# 3066MNPIRH register map
File version: 1.0
Registers are 32-bit, access per field, reset 0x0 unless marked. A register's access mark holds for its fields unless they carry their own. Offsets are from the block's base; [hi:lo] are bit positions.

## CAN — CAN peripheral interface
Base 0x14600000
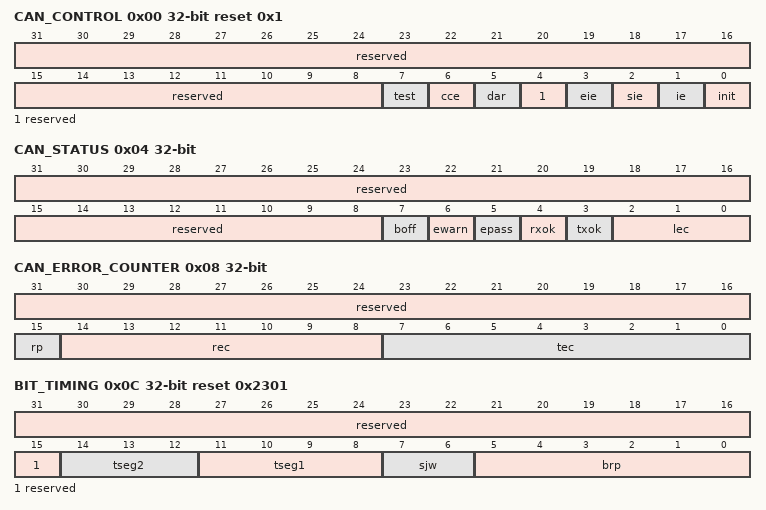
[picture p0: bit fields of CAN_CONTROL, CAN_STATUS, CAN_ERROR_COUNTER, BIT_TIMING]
0x00 CAN_CONTROL reset 0x1 — CAN_CONTROL为CAN 控制寄存器。
  [31:8] reserved ro — 保留。
  [7] test rw — 测试模式使能。 0：不使能； 1：使能。
  [6] cce rw — 更改配置使能。 0：禁止，CPU不能写Bit_Timing寄存器； 1：使能，当init为1时，CPU能写Bit_Timing寄存器。
  [5] dar rw — 关闭自动重传。 0：开启自动重传，自动重传受干扰的报文； 1：关闭自动重传。
  [4] reserved ro — 保留。
  [3] eie rw — 错误中断使能。 0：禁止； 1：使能错误中断，CAN_STATUS寄存器中的BOff或EWarn变化时会产生中断。
  [2] sie rw — 状态改变中断使能。 0：禁止； 1：使能状态改变中断，报文传输成功或检测到CAN总线错误时会产生中断。
  [1] ie rw — 模块中断使能。 0：禁止； 1：使能，CAN模块中断总开关。
  [0] init rw — 初始化使能。 0：禁止，此时CAN控制器正常工作； 1：使能，此时CAN控制器初始化。
0x04 CAN_STATUS — CAN_STATUS为CAN状态寄存器。
  [31:8] reserved ro — 保留。
  [7] boff ro — Bus-off状态。 0：CAN模块不处于Bus-off状态； 1：CAN模块处于Bus-off状态。
  [6] ewarn ro — 警告状态。 0：所有错误计数器均未达到96； 1：至少有一个错误计数器达到96。
  [5] epass ro — 错误状态。 0：处于CAN协议所定义的主动错误； 1：处于CAN协议所定义的被动错误。
  [4] rxok rw — 报文接收状态。 0：接收报文失败，rxok不会被CAN控制器复位； 1：接收报文成功（独立于报文接收过滤），rxok只有CPU可以清零。
  [3] txok rw — 报文发送状态。 0：发送报文失败，txok不会被CAN控制器复位； 1：发送报文成功（没有错误且被至少1个CAN节点应答），txok只有CPU可以清零。
  [2:0] lec rw — 错误状态码，用来表示CAN总线上最后一次错误状态。 000：无错误； 001：填充错误； 010：形式错误； 011：应答错误； 100：bit1错误； 101：bit0错误； 110：CRC错误； 111：未使用，没有检测到CAN总线事件，CPU最后将此值写入lec。
0x08 CAN_ERROR_COUNTER ro — CAN_ERROR_COUNTER为CAN错误计数寄存器。
  [31:16] reserved — 保留。
  [15] rp — 被动错误接收状态。 0：接收错误计数器未达到CAN协议所定义的被动错误水线； 1：接收错误计数器达到CAN协议所定义的被动错误水线。
  [14:8] rec — 接收错误计数器。 有效值在0～127。
  [7:0] tec — 发送错误计数器。 有效值在0～255。
0x0C BIT_TIMING reset 0x2301 — BIT_TIMING为位时间寄存器。
  [31:15] reserved ro — 保留。
  [14:12] tseg2 rw — 相位缓冲段2。 配置值为0～7，实际值比配置值多1。
  [11:8] tseg1 rw — 相位缓冲段1。 配置值为1～15，实际值比配置值多1。
  [7:6] sjw rw — 再同步跳转宽度。 配置值为0～3，实际值比配置值多1。
  [5:0] brp rw — 波特率系数。 配置值为0～63，实际值比配置值多1。
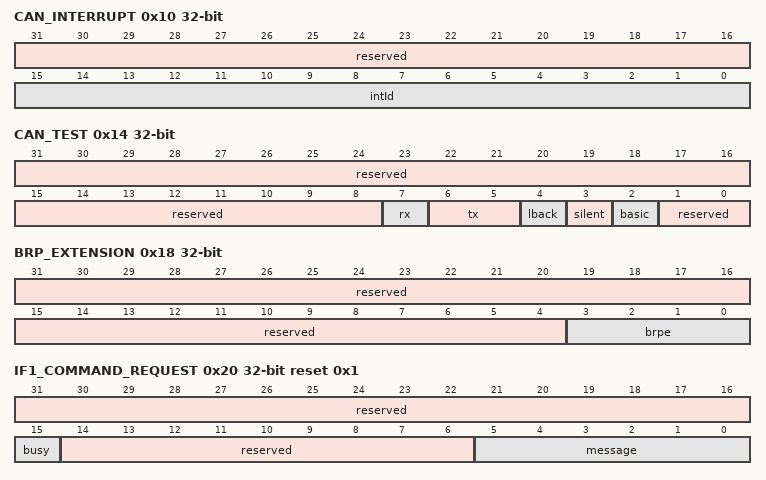
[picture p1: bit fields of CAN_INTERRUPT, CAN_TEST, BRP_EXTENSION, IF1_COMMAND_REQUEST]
0x10 CAN_INTERRUPT ro — CAN_INTERRUPT为CAN中断寄存器。
  [31:16] reserved — 保留。
  [15:0] intId — 中断ID。 0x0000：无中断； 0x0001：中断源是第1个报文对象； 0x0002：中断源是第2个报文对象； 0x0003：中断源是第3个报文对象； 0x0004：中断源是第4个报文对象； 0x0005：中断源是第5个报文对象； 0x0006：中断源是第6个报文对象； 0x0007：中断源是第7个报文对象； 0x0008：中断源是第8个报文对象； 0x0009：中断源是第9个报文对象； 0x000A：中断源是第10个报文对象； 0x000B：中断源是第11个报文对象； 0x000C：中断源是第12个报文对象； 0x000D：中断源是第13个报文对象； 0x000E：中断源是第14个报文对象； 0x000F：中断源是第15个报文对象； 0x0010：中断源是第16个报文对象； 0x0011：中断源是第17个报文对象； 0x0012：中断源是第18个报文对象； 0x0013：中断源是第19个报文对象； 0x0014：中断源是第20个报文对象； 0x0015：中断源是第21个报文对象； 0x0016：中断源是第22个报文对象； 0x0017：中断源是第23个报文对象； 0x0018：中断源是第24个报文对象； 0x0019：中断源是第25个报文对象； 0x001A：中断源是第26个报文对象； 0x001B：中断源是第27个报文对象； 0x001C：中断源是第28个报文对象； 0x001D：中断源是第29个报文对象； 0x001E：中断源是第30个报文对象； 0x001F：中断源是第31个报文对象； 0x0020：中断源是第32个报文对象； 0x0021 ～ 0x7FFF：无效； 0x8000：状态中断； 0x8001~0xFFFF：无效。
0x14 CAN_TEST — CAN_TEST为CAN调试寄存器。
  [31:8] reserved ro — 保留。
  [7] rx ro — CAN_RX管脚监控。 0：CAN总线为显性（CAN_RX=‘0’）； 1：CAN总线为隐形（CAN_RX=‘1’）。
  [6:5] tx rw — CAN_TX管脚控制。 00：不控制CAN_TX管脚； 01：采样点能被CAN_TX管脚监视； 10：CAN_TX管脚驱动显性值（‘0’）； 11：CAN_TX管脚驱动隐形值（‘1’）。
  [4] lback rw — Loop back模式使能。 0：禁止； 1：使能。
  [3] silent rw — Silent模式使能。 0：禁止； 1：使能。
  [2] basic rw — Basic模式使能。 0：禁止； 1：使能，此时IF1寄存器用作Tx Buffer，IF2寄存器用作Rx Buffer。
  [1:0] reserved ro — 保留。
0x18 BRP_EXTENSION — BRP_EXTENSION为BRP扩展寄存器。
  [31:4] reserved ro — 保留。
  [3:0] brpe rw — 波特率系数扩展。 扩展后的波特率系数有brpe和brp共同组成，其中高位是brpe，低位是brp。 此时，波特率系数的配置值最大可达到1023，实际值比配置值多1。
0x20 IF1_COMMAND_REQUEST reset 0x1 — IF1_COMMAND_REQUEST为IF1命令请求寄存器。
  [31:16] reserved ro — 保留。
  [15] busy ro — Busy标志。在Basic模式下，该位域可读可写。 0：IF1命令已经完成； 1：IF1命令执行中。
  [14:6] reserved ro — 保留。
  [5:0] message number rw — 报文对象序号。CPU写该位域后，IF1命令开始执行。 0x00：无效值，将指向0x20； 0x01 ～ 0x20：报文对象序号； 0x21 ~ 0x3F：无效值，将指向0x01 ~ 0x1F。
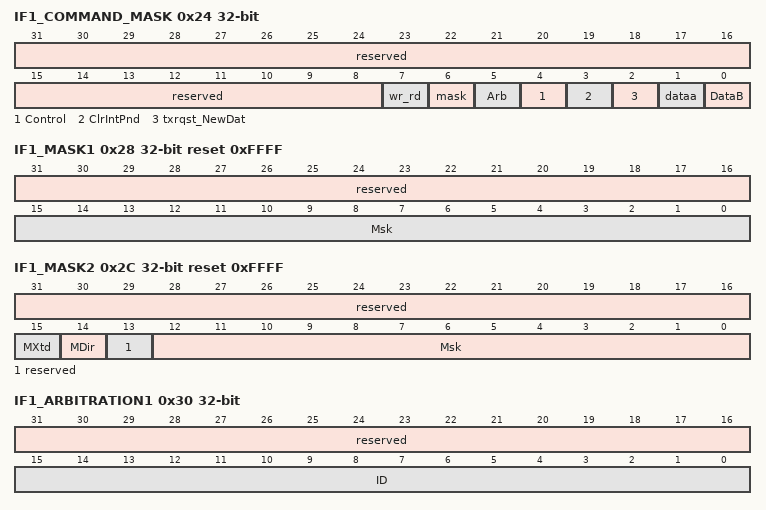
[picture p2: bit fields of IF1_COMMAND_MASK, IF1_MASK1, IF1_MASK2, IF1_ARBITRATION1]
0x24 IF1_COMMAND_MASK — IF1_COMMAND_MASK为IF1命令掩码寄存器。
  [31:8] reserved ro — 保留。
  [7] wr_rd rw — 读写命令，控制IF1报文缓冲寄存器和Message RAM传输方向。 0：读命令，将Message RAM中存储的报文对象回读到IF1报文缓冲寄存器； 1：写命令，将IF1报文缓冲寄存器写入到Message RAM中存储的报文对象。
  [6] mask rw — 命令掩码，控制IF1_MASK的传输。 当wr_rd为1，写命令时： 0：不写入，报文对象的msk、mdir、mxtd不改变； 1：将IF1_MASK1和IF1_MASK2寄存器中的msk、mdir、mxtd写入报文对象。 当wr_rd为0，读命令时： 0：不回读，IF1_MASK不改变； 1：将报文对象的Msk、Mdir、mxtd回读到IF1_MASK1和IF1_MASK2寄存器中。
  [5] Arb rw — 命令掩码，控制IF1_ARBITRATION的传输。 当wr_rd寄存器为1，写命令时： 0：不写入，报文对象的ID、Dir、Xtd、MsgVal不改变； 1：将IF1_ARBITRATION1和IF1_ARBITRATION2中的ID、Dir、Xtd、MsgVal位写入报文对象。 当wr_rd寄存器为0，读命令时： 0：不回读，IF1_ ARBITRATION不改变； 1：将报文对象的ID、Dir、Xtd、MsgVal回读到IF1_ARBITRATION1和IF1_ARBITRATION2寄存器中。
  [4] Control rw — 命令掩码，控制IF1_MESSAGE_CONTROL的传输。 当wr_rd寄存器为1，写命令时： 0：不写入，报文对象中的IF1_MESSAGE_CONTROL相关bit位不改变； 1：将IF1_MESSAGE_CONTROL的bit位写入报文对象。 当wr_rd寄存器为0，读命令时： 0：不回读，IF1_MESSAGE_CONTROL不改变； 1：将报文对象中的相应bit位回读到IF1_MESSAGE_CONTROL寄存器中。
  [3] ClrIntPnd rw — 命令掩码，清除报文对象的中断待处理。 当wr_rd寄存器为1，写命令时： 该位域忽略。 当wr_rd寄存器为0，读命令时： 0：报文对象的IntPnd位保持不变； 1：清除报文对象的IntPnd位。
  [2] txrqst_NewDat rw — 命令掩码，控制报文对象的txrqst位或者NewDat位。 当wr_rd寄存器为1时，写命令时： 访问txrqst位。 0：将IF1_MESSAGE_CONTROL寄存器的txrqst位写入报文对象； 1：忽略IF1_MESSAGE_CONTROL寄存器的txrqst位。直接置位报文对象的txrqst位，请求报文发送。 当wr_rd为0时，读命令时： 访问newdat位，IF1_MESSAGE_CONTROL寄存器的newdata位不会被更新。 0：报文对象的newdat位均保持不变； 1：清除报文对象的newdat位。
  [1] dataa rw — 命令掩码，控制IF1_DATAA的传输。 当wr_rd为1时，写命令时： 0：报文对象中的数据Byte 0～3保持不变； 1：将IF1_DATAA寄存器写入报文对象，更新报文对象中的数据Byte0~3。 当wr_rd寄存器为0时，读命令时： 0：IF1_DATAA寄存器保持不变； 1：将报文对象中的数据Byte0~3回读到IF1_DATAA寄存器中。
  [0] DataB rw — 命令掩码，控制IF1_DATAB的传输。 当wr_rd寄存器为1时，写命令时： 0：报文对象中的数据Byte 4～7保持不变； 1：将IF1_DATAB寄存器写入报文对象，更新报文对象中的数据Byte4~7。 当wr_rd寄存器为0时，读命令时： 0：IF1_DATAB寄存器保持不变； 1：将报文对象中的数据Byte4~7回读到IF1_DATAB寄存器中。
0x28 IF1_MASK1 reset 0xFFFF — IF1_MASK1为IF1掩码寄存器1。
  [31:16] reserved ro — 保留。
  [15:0] Msk rw — 报文对象ID第15位至第0位掩码，用于报文接收过滤。 0：ID第15位至第0位不用于报文接收过滤； 1：ID第15位至第0位用于报文接收过滤。
0x2C IF1_MASK2 reset 0xFFFF — IF1_MASK2为IF1掩码寄存器2。
  [31:16] reserved ro — 保留。
  [15] MXtd rw — 报文对象的拓展ID位（Xtd）掩码，用于接收报文过滤。 0：Xtd不用于报文接收过滤； 1：Xtd用于报文接收过滤。
  [14] MDir rw — 报文对象的方向位（Dir）掩码，用于接收报文过滤。 0：Dir不用于报文接收过滤； 1：Dir用于报文接收过滤。
  [13] reserved ro — 保留。
  [12:0] Msk rw — 报文对象ID第28位至第16位掩码，用于接收报文过滤。 0：ID第28位至第16位不用于报文接收过滤； 1：ID第28位至第16位用于报文接收过滤。
0x30 IF1_ARBITRATION1 — IF1_ARBITRATION1为IF1仲裁寄存器1。
  [31:16] reserved ro — 保留。
  [15:0] ID rw — 报文对象的报文ID第15位至第0位。 注意： 当报文对象用于收发扩展帧时，应使用全部ID；当报文对象用于收发标准帧时，应使用IF1_ARBITRATION2[ID]的高11位。
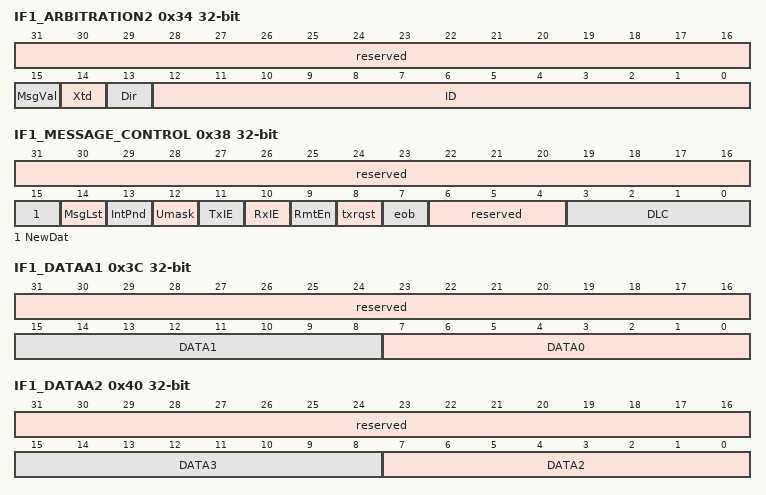
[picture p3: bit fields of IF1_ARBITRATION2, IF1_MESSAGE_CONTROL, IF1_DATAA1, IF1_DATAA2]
0x34 IF1_ARBITRATION2 — IF1_ARBITRATION2为IF1仲裁寄存器2。
  [31:16] reserved ro — 保留。
  [15] MsgVal rw — 报文对象有效使能。 0：禁止，该报文对象无效； 1：使能，该报文对象有效。
  [14] Xtd rw — 报文对象收发帧格式。 0：该报文对象收发标准格式帧； 1：该报文对象收发扩展格式帧。
  [13] Dir rw — 报文对象的方向。 0：报文对象为接收方向，接收报文； 1：报文对象为发送方向，发送报文。
  [12:0] ID rw — 报文对象的报文ID第28位至第16位。 注意： 当报文对象用于收发扩展帧时，应使用全部ID； 当报文对象用于收发标准帧时，应使用IF2_ARBITRATION2[ID]的高11位
0x38 IF1_MESSAGE_CONTROL — IF1_MESSAGE_CONTROL为IF1报文控制寄存器。
  [31:16] reserved ro — 保留。
  [15] NewDat rw — 报文对象的新数据写入状态。 报文对象为发送方向时： 0：无新的帧数据写入报文对象，报文对象成功发送后会清除报文对象中的NewDat； 1：有新的帧数据写入报文对象。 报文对象为接收方向时： 0：报文对象没有接收到新的帧； 1：报文对象接收到了新的帧。
  [14] MsgLst rw — 报文对象的报文丢失标识（仅在报文对象为接收方向时有效）。 0：报文对象无报文丢失； 1：报文对象有报文丢失，当报文对象的NewDat位未被清除，新的报文已接收时，报文对象的MsgLst置1。
  [13] IntPnd rw — 报文对象的中断待处理标识。 0：该报文对象不是中断源； 1：该报文对象是中断源。
  [12] Umask rw — 报文对象是否使用报文掩码，用于报文接收过滤。 0：不使用； 1：使用相关掩码位（Msk28～0，mxtd和Mdir用于报文接收过滤。
  [11] TxIE rw — 发送中断使能。 0：不使能，帧发送成功后IntPnd保持不变； 1：使能，帧发送成功后IntPnd将被至1。
  [10] RxIE rw — 接收中断使能。 0：不使能，帧接收成功后IntPnd保持不变； 1：使能，帧接收成功后IntPnd将被至1。
  [9] RmtEn rw — 远程帧使能。 0：不使能，接收远程帧后txrqst保持不变； 1：使能，接收远程帧后txrqst置1。
  [8] txrqst rw — 传输请求。 0：该报文对象没在等待传输； 1：该报文对象请求传输，并且还没传输完成。
  [7] eob rw — 多报文接收模式。 0：该报文对象不是多报文接收模式中最后一个报文对象； 1：该报文对象是单一报文或是多报文接收模式中最后一个报文对象。
  [6:4] reserved ro — 保留。
  [3:0] DLC rw — 数据长度编码。 0x0～0x8：数据帧有0~8个数据字节； 0x9~0xF：数据帧有8个数据字节。
0x3C IF1_DATAA1 — IF1_DATAA1为IF1数据A1寄存器。
  [31:16] reserved ro — 保留。
  [15:8] DATA1 rw — CAN帧数据Byte 1。
  [7:0] DATA0 rw — CAN帧数据Byte 0。
0x40 IF1_DATAA2 — IF1_DATAA2为IF1数据A2寄存器。
  [31:16] reserved ro — 保留。
  [15:8] DATA3 rw — CAN帧数据Byte 3。
  [7:0] DATA2 rw — CAN帧数据Byte 2。
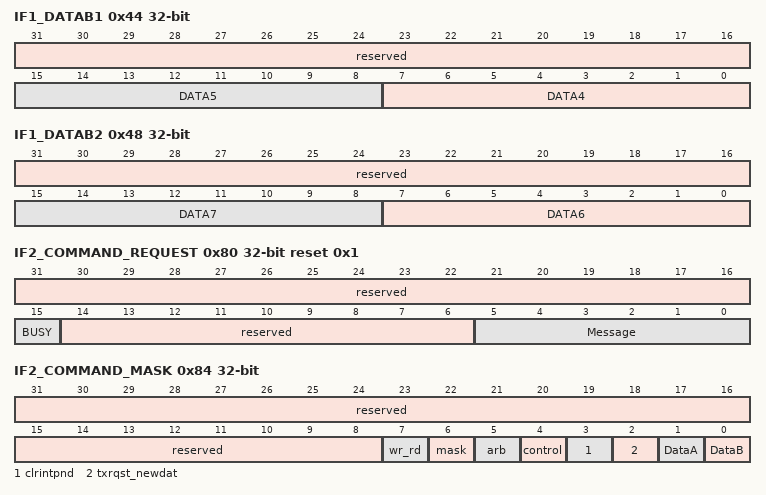
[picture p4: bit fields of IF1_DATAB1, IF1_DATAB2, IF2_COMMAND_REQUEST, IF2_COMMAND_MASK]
0x44 IF1_DATAB1 — IF1_DATAB1为IF1数据B1寄存器。
  [31:16] reserved ro — 保留。
  [15:8] DATA5 rw — CAN帧数据Byte 5。
  [7:0] DATA4 rw — CAN帧数据Byte 4。
0x48 IF1_DATAB2 — IF1_DATAB2为IF1数据B2寄存器。
  [31:16] reserved ro — 保留。
  [15:8] DATA7 rw — CAN帧数据Byte 7。
  [7:0] DATA6 rw — CAN帧数据Byte 6。
0x80 IF2_COMMAND_REQUEST reset 0x1 — IF2_COMMAND_REQUEST为IF2命令请求寄存器。
  [31:16] reserved ro — 保留。
  [15] BUSY ro — Busy标志。 0：IF2命令已经完成； 1：IF2命令执行中。
  [14:6] reserved ro — 保留。
  [5:0] Message Number rw — 报文对象序号。CPU写该位域后，IF2命令开始执行。 0x00：无效值，将指向0x20； 0x01～0x20：报文对象序号； 0x21~0x3F：无效值，将指向0x01~0x1F。
0x84 IF2_COMMAND_MASK — IF2_COMMAND_MASK为IF2命令掩码寄存器。
  [31:8] reserved ro — 保留。
  [7] wr_rd rw — 读写命令，控制IF2报文缓冲寄存器和Message RAM传输方向。 0：读命令，将Message RAM中存储的报文对象回读到IF2报文缓冲寄存器； 1：写命令，将IF2报文缓冲寄存器写入到Message RAM中存储的报文对象。
  [6] mask rw — 命令掩码，控制IF2_MASK的传输。 当wr_rd寄存器为1，写命令时： 0：不写入，报文对象的ID Mask、mdir、mxtd不改变； 1：将IF2_MASK1和IF2_MASK2寄存器中的ID Mask、mdir、mxtd写入报文对象。 当wr_rd寄存器为0，读命令时： 0：不回读，IF2_MASK不改变； 1：将报文对象的ID Mask、mdir、mxtd回读到IF2_MASK1和IF2_MASK2寄存器中。
  [5] arb rw — 命令掩码，控制IF2_ARBITRATION的传输。 当wr_rd寄存器为1，写命令时： 0：不写入，报文对象的ID、dir、xtd、msgval不改变； 1：将IF2_ARBITRATION1和IF2_ARBITRATION2中的ID、dir、xtd、msgval位写入报文对象。 当wr_rd寄存器为0，读命令时： 0：不回读，IF2_ARBITRATION不改变； 1：将报文对象的ID、dir、xtd、msgval回读到IF2_ARBITRATION1和IF2_ARBITRATION2寄存器中。
  [4] control rw — 命令掩码，控制IF2_MESSAGE_CONTROL的传输。 当wr_rd寄存器为1，写命令时： 0：不写入，报文对象中的IF2_MESSAGE_CONTROL相关bit位不改变； 1：将IF2_MESSAGE_CONTROL的bit位写入报文对象。 当wr_rd寄存器为0，读命令时： 0：不回读，IF2_MESSAGE_CONTROL不改变； 1：将报文对象中的相应bit位回读到IF2_MESSAGE_CONTROL寄存器中。
  [3] clrintpnd rw — 命令掩码，清除报文对象的中断待处理。 当wr_rd寄存器为1，写命令时： 该位域忽略。 当wr_rd寄存器为0，读命令时： 0：报文对象的intpnd位保持不变； 1：清除报文对象的intpnd位。
  [2] txrqst_newdat rw — 命令掩码，控制报文对象的txrqst位或者NewDat位。 当wr_rd寄存器为1时，写命令时： 访问txrqst位。 0：报文对象txrqst位保持不变； 1：置位报文对象的txrqst位，请求报文发送。 当wr_rd寄存器为0时，读命令时： 访问newdat位。 0：报文对象的newdat位保持不变； 1：清除报文对象的newdat位。
  [1] DataA rw — 命令掩码，控制IF2_DATAA的传输。 当wr_rd寄存器为1时，写命令时： 0：报文对象中的数据Byte 0～3保持不变； 1：将IF2_DATAA寄存器写入报文对象，更新报文对象中的数据Byte0~3。 当wr_rd寄存器为0时，读命令时： 0：IF2_DATAA寄存器保持不变； 1：将报文对象中的数据Byte0~3回读到IF2_DATAA寄存器中。
  [0] DataB rw — 命令掩码，控制IF2_DATAB的传输。 当wr_rd寄存器为1时，写命令时： 0：报文对象中的数据Byte 4～7保持不变； 1：将IF2_DATAB寄存器写入报文对象，更新报文对象中的数据Byte4~7。 当wr_rd寄存器为0时，读命令时： 0：IF2_DATAB寄存器保持不变； 1：将报文对象中的数据Byte4~7回读到IF2_DATAB寄存器中。
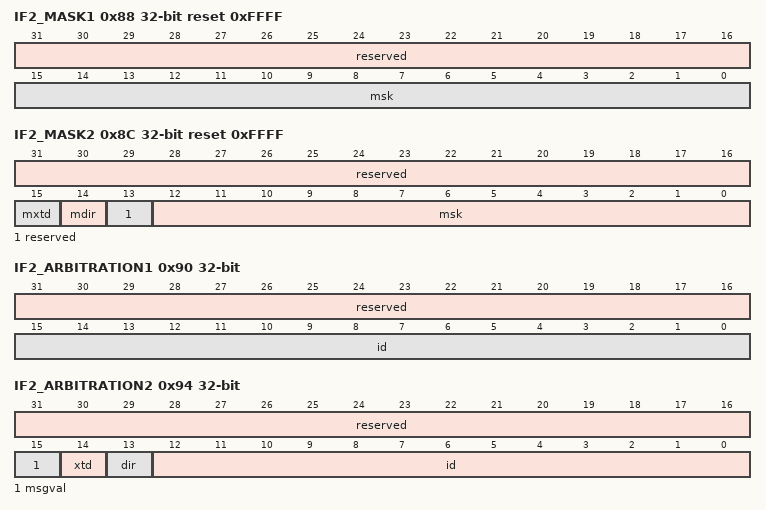
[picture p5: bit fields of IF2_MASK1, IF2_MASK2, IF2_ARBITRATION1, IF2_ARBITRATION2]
0x88 IF2_MASK1 reset 0xFFFF — IF2_MASK1为IF2掩码寄存器1。
  [31:16] reserved ro — 保留。
  [15:0] msk rw — 报文对象ID第15位至第0位掩码，用于报文接收过滤。 0：ID第15位至第0位不用于报文接收过滤； 1：ID第15位至第0位用于报文接收过滤。
0x8C IF2_MASK2 reset 0xFFFF — IF2_MASK2为IF2掩码寄存器2。
  [31:16] reserved ro — 保留。
  [15] mxtd rw — 报文对象的拓展ID位（xtd）掩码，用于报文接收过滤。 0：xtd不用于报文接收过滤； 1：xtd用于报文接收过滤。
  [14] mdir rw — 报文对象的方向位（dir）掩码，用于报文接收过滤。 0：dir不用于报文接收过滤； 1：dir用于报文接收过滤。
  [13] reserved ro — 保留。
  [12:0] msk rw — 报文对象ID第28位至第16位掩码，用于报文接收过滤。 0：ID第28位至第16位不用于报文接收过滤； 1：ID第28位至第16位用于报文接收过滤。
0x90 IF2_ARBITRATION1 — IF2_ARBITRATION1为IF2仲裁寄存器1。
  [31:16] reserved ro — 保留。
  [15:0] id rw — 报文对象的报文ID第15位至第0位。 注意： 当报文对象用于收发扩展帧时，应使用全部ID；当报文对象用于收发标准帧时，应使用IF2_ARBITRATION2[id]的高11位。
0x94 IF2_ARBITRATION2 — IF2_ARBITRATION2为IF2仲裁寄存器2。
  [31:16] reserved ro — 保留。
  [15] msgval rw — 报文对象有效使能。 0：禁止，该报文对象无效； 1：使能，该报文对象有效。
  [14] xtd rw — 报文对象收发帧格式。 0：该报文对象收发标准格式帧； 1：该报文对象收发扩展格式帧。
  [13] dir rw — 报文对象的方向。 0：报文对象为接收方向，接收报文； 1：报文对象为发送方向，发送报文。
  [12:0] id rw — 报文对象的报文id第28位至第16位。 注意： 当报文对象用于收发扩展帧时，应使用全部id；当报文对象用于收发标准帧时，应使用IF2_ARBITRATION2[id]的高11位。
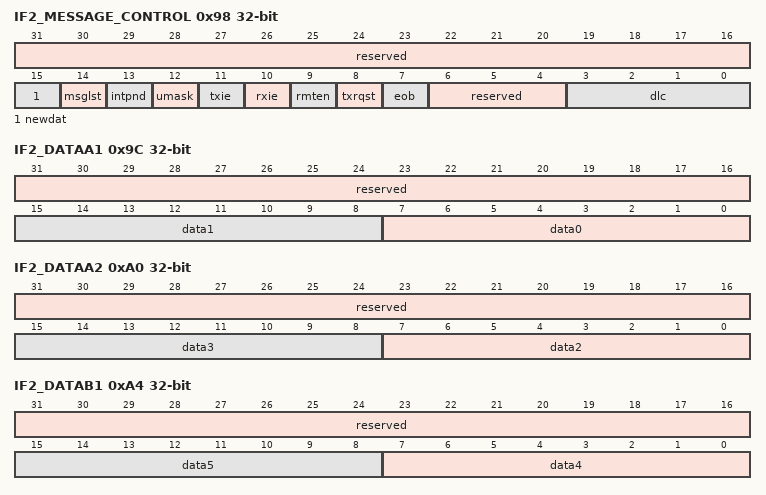
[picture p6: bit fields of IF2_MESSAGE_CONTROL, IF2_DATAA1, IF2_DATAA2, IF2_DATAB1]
0x98 IF2_MESSAGE_CONTROL — IF2_MESSAGE_CONTROL为IF2报文控制寄存器。
  [31:16] reserved ro — 保留。
  [15] newdat rw — 报文对象的帧数据标识。 报文对象为发送方向时： 0：无新的帧数据写入报文对象，报文对象成功发送后会清除报文对象中的newdat； 1：有新的帧数据写入报文对象。 报文对象为接收方向时： 0：报文对象没有接收到新的帧； 1：报文对象接收到了新的帧。
  [14] msglst rw — 报文对象的报文丢失标识（仅在报文对象为接收方向时有效）。 0：报文对象无报文丢失； 1：报文对象有报文丢失，当报文对象的newdat位未被清除，新的报文已接收时，报文对象的msglst置1。
  [13] intpnd rw — 报文对象的中断待处理标识。 0：该报文对象不是中断源； 1：该报文对象是中断源。
  [12] umask rw — 报文对象是否使用报文掩码，用于报文接收过滤。 0：不使用； 1：使用相关掩码位（Msk28-0，mxtd和mdir）用于报文接收过滤。
  [11] txie rw — 发送中断使能。 0：不使能，帧发送成功后intpnd保持不变； 1：使能，帧发送成功后intpnd将被至1。
  [10] rxie rw — 接收中断使能。 0：不使能，帧接收成功后intpnd保持不变； 1：使能，帧接收成功后intpnd将被至1。
  [9] rmten rw — 远程帧使能。 0：不使能，接收远程帧后txrqst保持不变； 1：使能，接收远程帧后txrqst置1。
  [8] txrqst rw — 传输请求。 0：该报文对象没在等待传输； 1：该报文对象请求传输，并且还没传输完成。
  [7] eob rw — 多报文接收模式。 0：该报文对象不是多报文接收模式中最后一个报文对象； 1：该报文对象是单一报文或是多报文接收模式中最后一个报文对象。
  [6:4] reserved ro — 保留。
  [3:0] dlc rw — 数据长度编码。 0x0～0x8：数据帧有0-8个数据字节； 0x9~0xF：数据帧有8个数据字节。
0x9C IF2_DATAA1 — IF2_DATAA1为IF2数据A1寄存器。
  [31:16] reserved ro — 保留。
  [15:8] data1 rw — CAN帧数据Byte 1。
  [7:0] data0 rw — CAN帧数据Byte 0。
0xA0 IF2_DATAA2 — IF2_DATAA2为IF2数据A2寄存器。
  [31:16] reserved ro — 保留。
  [15:8] data3 rw — CAN帧数据Byte 3。
  [7:0] data2 rw — CAN帧数据Byte 2。
0xA4 IF2_DATAB1 — IF2_DATAB1为IF2数据B1寄存器。
  [31:16] reserved ro — 保留。
  [15:8] data5 rw — CAN帧数据Byte 5。
  [7:0] data4 rw — CAN帧数据Byte 4。
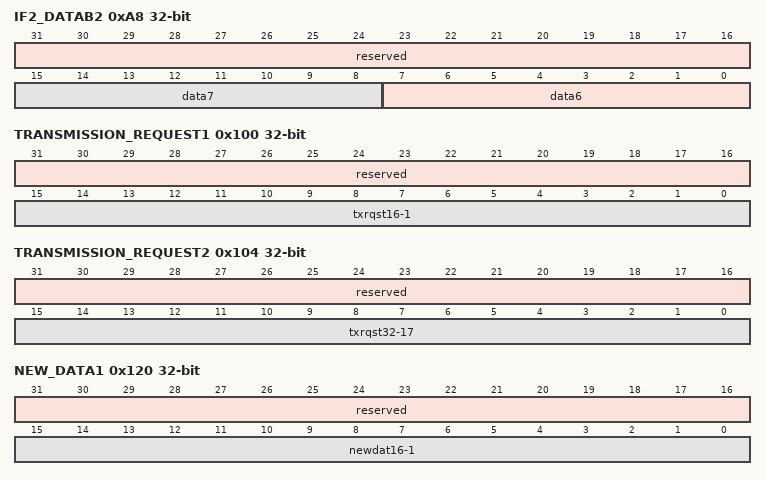
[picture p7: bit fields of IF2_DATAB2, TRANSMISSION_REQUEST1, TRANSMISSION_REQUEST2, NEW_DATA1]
0xA8 IF2_DATAB2 — IF2_DATAB2为IF2数据B2寄存器。
  [31:16] reserved ro — 保留。
  [15:8] data7 rw — CAN帧数据Byte 7。
  [7:0] data6 rw — CAN帧数据Byte 6。
0x100 TRANSMISSION_REQUEST1 ro — TRANSMISSION_REQUEST1为传输请求状态寄存器1。
  [31:16] reserved — 保留。
  [15:0] txrqst16-1 — 传输请求状态（txrqst16-1每bit分别对应报文对象16-1）。CPU可以回读检查传输请求中的报文对象。CPU可以通过IF报文对象接口寄存器组，配置报文对象发出传输请求。 0：该报文对象没有等待传输； 1：该报文对象请求发送，并且还没传输完成。
0x104 TRANSMISSION_REQUEST2 ro — TRANSMISSION_REQUEST2为传输请求状态寄存器2。
  [31:16] reserved — 保留。
  [15:0] txrqst32-17 — 传输请求状态（txrqst32-17每bit分别对应报文对象32-17）。CPU可以回读检查传输请求中的报文对象。CPU可以通过IF报文对象接口寄存器组，配置报文对象发出传输请求。 0：该报文对象没有等待传输； 1：该报文对象请求发送，并且还没传输完成。
0x120 NEW_DATA1 ro — NEW_DATA1为新数据状态寄存器1。
  [31:16] reserved — 保留。
  [15:0] newdat16-1 — 新数据写入状态（newdat16-1每bit分别对应报文对象16-1）。CPU可以回读检查报文对象是否接收到新的数据帧。CPU可以通过IF报文对象接口寄存器组，配置报文对象newdat位域置位或清零。CAN控制器的报文对象在接收报文成功后，相应的newdat自动置位。 0：无新数据写入该报文对象； 1：有新数据写入该报文对象。
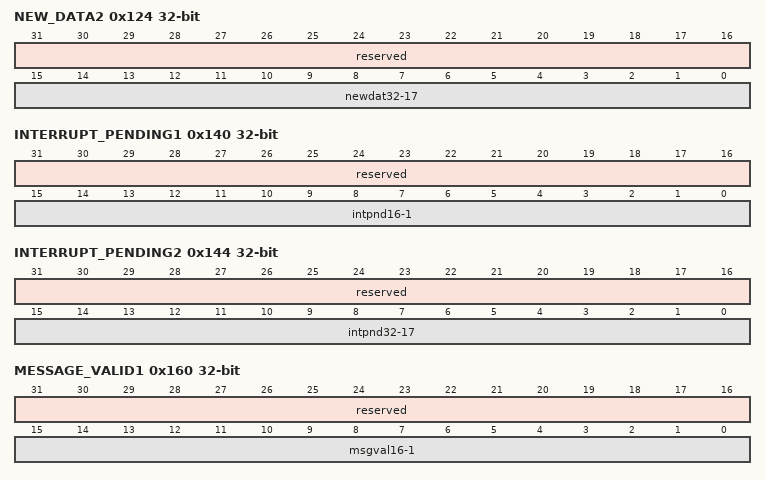
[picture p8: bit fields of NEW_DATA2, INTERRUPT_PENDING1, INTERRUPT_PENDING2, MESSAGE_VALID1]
0x124 NEW_DATA2 ro — NEW_DATA2为新数据状态寄存器2。
  [31:16] reserved — 保留。
  [15:0] newdat32-17 — 新数据写入状态（newdat32-17每bit分别对应报文对象32-17）。CPU可以回读检查报文对象是否接收到新的数据帧。CPU可以通过IF报文对象接口寄存器组，配置报文对象newdat位域置位或清零。CAN控制器的报文对象在接收报文成功后，相应的newdat自动置位。 0：无新数据写入该报文对象； 1：有新数据写入该报文对象。
0x140 INTERRUPT_PENDING1 ro — INTERRUPT_PENDING1为中断待处理状态寄存器1。
  [31:16] reserved — 保留。
  [15:0] intpnd16-1 — 中断待处理状态（intpnd16-1每bit分别对应报文对象16-1）。CPU可以回读检查报文对象是否是中断源。CPU可以通过IF报文对象接口寄存器组，配置报文对象intpnd位域置位或清零。CAN控制器的报文对象在接收报文成功后，或者发送报文成功后，相应的intpnd自动置位。 0：该报文对象不是中断源； 1：该报文对象是中断源。
0x144 INTERRUPT_PENDING2 ro — INTERRUPT_PENDING2为中断待处理状态寄存器2。
  [31:16] reserved — 保留。
  [15:0] intpnd32-17 — 中断待处理状态（intpnd32-17每bit分别对应报文对象32-17）。CPU可以回读检查报文对象是否是中断源。CPU可以通过IF报文对象接口寄存器组，配置报文对象IntPnd位域置位或清零。CAN控制器的报文对象在接收报文成功后，或者发送报文成功后，相应的intpnd自动置位。 0：该报文对象不是中断源； 1：该报文对象是中断源。
0x160 MESSAGE_VALID1 ro — MESSAGE_VALID1为报文有效状态寄存器1。
  [31:16] reserved — 保留。
  [15:0] msgval16-1 — 报文对象有效状态（msgval16-1每bit分别对应报文对象16-1）。CPU可以回读检查报文对象是否有效。CPU可以通过IF报文对象接口寄存器组，配置报文对象msgval位域置位或清零。 0：该报文对象无效； 1：该报文对象有效。
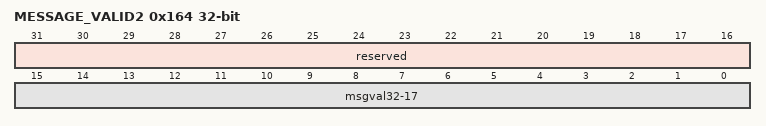
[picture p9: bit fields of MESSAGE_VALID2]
0x164 MESSAGE_VALID2 ro — MESSAGE_VALID2为报文有效状态寄存器2。
  [31:16] reserved — 保留。
  [15:0] msgval32-17 — 报文对象有效状态（msgval32-17每bit分别对应报文对象32-17）。CPU可以回读检查报文对象是否有效。CPU可以通过IF报文对象接口寄存器组，配置报文对象msgval位域置位或清零。 0：该报文对象无效； 1：该报文对象有效。
